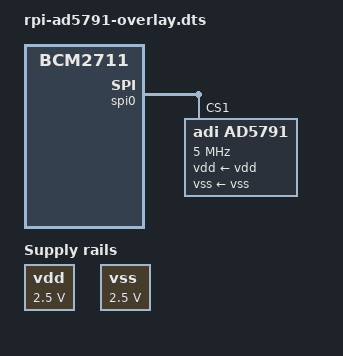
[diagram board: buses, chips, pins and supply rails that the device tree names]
// SPDX-License-Identifier: GPL-2.0
/dts-v1/;
/plugin/;

/ {
	compatible = "brcm,bcm2835", "brcm,bcm2708", "brcm,bcm2709", "brcm,bcm2711";
};

&{/} {
	vdd: fixedregulator@0 {
		compatible = "regulator-fixed";
		regulator-name = "fixed-supply";
		regulator-min-microvolt = <2500000>;
		regulator-max-microvolt = <2500000>;
		regulator-boot-on;
	};
};

&{/} {
	vss: fixedregulator@1 {
		compatible = "regulator-fixed";
		regulator-name = "fixed-supply";
		regulator-min-microvolt = <2500000>;
		regulator-max-microvolt = <2500000>;
		regulator-boot-on;
	};
};

&spi0 {
	#address-cells = <1>;
	#size-cells = <0>;
	status = "okay";

	ad5791@1 {
		compatible = "adi,ad5791";
		reg = <1>;
		spi-max-frequency = <5000000>;
		spi-cpha;
		vdd-supply = <&vdd>;
		vss-supply = <&vss>;
	};
};

&spidev0 {
	status = "disabled";
};

&spidev1 {
	status = "disabled";
};
